AUTOSAR XML (schema 00046)
package /MICROSAR/BswM_swc
  4 x mode declaration group:
    ESH_Mode: initial-mode=STARTUP
      5 x mode:
        STARTUP
        RUN
        POSTRUN
        WAKEUP
        SHUTDOWN
    ESH_RunRequest: initial-mode=RELEASED
      mode RELEASED
      mode REQUESTED
    ModeDecl_ComFault_State: initial-mode=ComFaultPreCond_FAIL
      mode ComFaultPreCond_PASS
      mode ComFaultPreCond_FAIL
    ModeDecl_ComFault_State_WithKL15: initial-mode=ComFaultPreCondWithKL15_FAIL
      mode ComFaultPreCondWithKL15_FAIL
      mode ComFaultPreCondWithKL15_PASS
  data type mapping set BswMMappingSet  # Contains Mapping for ModeDeclarations Groups which are provided by BswM.
    mode-request-type-maps:
      implementation-data-type=BswM_ModeDecl_ComFault_State, mode-group=ModeDecl_ComFault_State
      implementation-data-type=BswM_ModeDecl_ComFault_State_WithKL15, mode-group=ModeDecl_ComFault_State_WithKL15
      implementation-data-type=BswM_ESH_Mode, mode-group=ESH_Mode
      implementation-data-type=BswM_ESH_RunRequest, mode-group=ESH_RunRequest
package /MICROSAR/BswM_swc/ComponentTypes
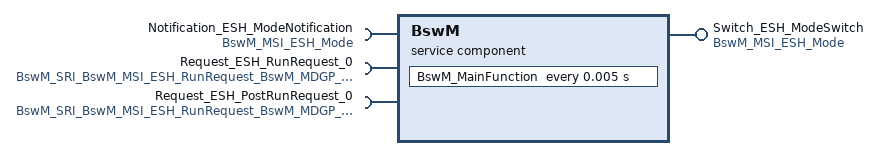
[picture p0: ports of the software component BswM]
  service sw component type BswM: category=SERVICE_COMPONENT
    provide port Switch_ESH_ModeSwitch: provided-interface=BswM_MSI_ESH_Mode
    require port Notification_ESH_ModeNotification: required-interface=BswM_MSI_ESH_Mode
    require port Request_ESH_RunRequest_0: nonqueued-receiver-com-spec{data-element=BswM_SRI_BswM_MSI_ESH_RunRequest_BswM_MDGP_ESH_RunRequest/requestedMode, handle-out-of-range-status=SILENT, init-value=RELEASED}, required-interface=BswM_SRI_BswM_MSI_ESH_RunRequest_BswM_MDGP_ESH_RunRequest
    require port Request_ESH_PostRunRequest_0: nonqueued-receiver-com-spec{data-element=BswM_SRI_BswM_MSI_ESH_RunRequest_BswM_MDGP_ESH_RunRequest/requestedMode, handle-out-of-range-status=SILENT, init-value=RELEASED}, required-interface=BswM_SRI_BswM_MSI_ESH_RunRequest_BswM_MDGP_ESH_RunRequest
    behavior BswMInternalBehavior: data-type-mapping=BswMMappingSet, handle-termination-and-restart=NO-SUPPORT, included-data-type-set=data-type=[BswM_ModeDecl_ComFault_State, BswM_ModeDecl_ComFault_State_WithKL15, BswM_ESH_Mode, BswM_ESH_RunRequest]
      timing event Timer_BswM_MainFunction: start-on-event=BswM_MainFunction, period=0.005
      port-api-options:
        enable-take-address=true, indirect-api=false, port=Switch_ESH_ModeSwitch
        enable-take-address=true, indirect-api=false, port=Notification_ESH_ModeNotification
        enable-take-address=true, indirect-api=false, port=Request_ESH_RunRequest_0
        enable-take-address=true, indirect-api=false, port=Request_ESH_PostRunRequest_0
      runnable BswM_MainFunction: mode-access-point=Notification_ESH_ModeNotification.BswM_MDGP_ESH_Mode
        data-receive-point-by-arguments:
          access DataReceivePointBswM_MainFunction_Request_ESH_RunRequest_0_requestedMode: accessed-variable=Request_ESH_RunRequest_0.requestedMode
          access DataReceivePointBswM_MainFunction_Request_ESH_PostRunRequest_0_requestedMode: accessed-variable=Request_ESH_PostRunRequest_0.requestedMode
        mode switch point ModeSwitchPointBswM_MainFunction_Switch_ESH_ModeSwitch_BswM_MDGP_ESH_Mode: mode-group=Switch_ESH_ModeSwitch.BswM_MDGP_ESH_Mode
  swc implementation BswMImplementation: programming-language=C, behavior=BswMInternalBehavior
package /MICROSAR/BswM_swc/DataTypes
  4 x impl type, all with category=TYPE_REFERENCE, range raw 0..255, implementation-data-type=uint8:
    BswM_ESH_Mode: compu {0=STARTUP, 1=RUN, 2=POSTRUN, 3=WAKEUP, 4=SHUTDOWN}  # Unique value for each user
    BswM_ESH_RunRequest: compu {0=RELEASED, 1=REQUESTED}  # Unique value for each user
    BswM_ModeDecl_ComFault_State: compu {1=ComFaultPreCond_PASS, 0=ComFaultPreCond_FAIL}  # Unique value for each user
    BswM_ModeDecl_ComFault_State_WithKL15: compu {0=ComFaultPreCondWithKL15_FAIL, 1=ComFaultPreCondWithKL15_PASS}  # Unique value for each user
package /MICROSAR/BswM_swc/Interfaces
  mode switch interface BswM_MSI_ESH_Mode: is-service=true, service-kind=BASIC-SOFTWARE-MODE-MANAGER
    mode group BswM_MDGP_ESH_Mode: type=ESH_Mode
  sender receiver interface BswM_SRI_BswM_MSI_ESH_Mode_BswM_MDGP_ESH_Mode: is-service=true, service-kind=BASIC-SOFTWARE-MODE-MANAGER
    data requestedMode: type=BswM_ESH_Mode
  mode switch interface BswM_MSI_ESH_RunRequest: is-service=true, service-kind=BASIC-SOFTWARE-MODE-MANAGER
    mode group BswM_MDGP_ESH_RunRequest: type=ESH_RunRequest
  sender receiver interface BswM_SRI_BswM_MSI_ESH_RunRequest_BswM_MDGP_ESH_RunRequest: is-service=true, service-kind=BASIC-SOFTWARE-MODE-MANAGER
    data requestedMode: type=BswM_ESH_RunRequest
  mode switch interface BswM_MSI_ModeDecl_ComFault_State: is-service=true, service-kind=BASIC-SOFTWARE-MODE-MANAGER
    mode group BswM_MDGP_ModeDecl_ComFault_State: type=ModeDecl_ComFault_State
  sender receiver interface BswM_SRI_BswM_MSI_ModeDecl_ComFault_State_BswM_MDGP_ModeDecl_ComFault_State: is-service=true, service-kind=BASIC-SOFTWARE-MODE-MANAGER
    data requestedMode: type=BswM_ModeDecl_ComFault_State
  mode switch interface BswM_MSI_ModeDecl_ComFault_State_WithKL15: is-service=true, service-kind=BASIC-SOFTWARE-MODE-MANAGER
    mode group BswM_MDGP_ModeDecl_ComFault_State_WithKL15: type=ModeDecl_ComFault_State_WithKL15
  sender receiver interface BswM_SRI_BswM_MSI_ModeDecl_ComFault_State_WithKL15_BswM_MDGP_ModeDecl_ComFault_State_WithKL15: is-service=true, service-kind=BASIC-SOFTWARE-MODE-MANAGER
    data requestedMode: type=BswM_ModeDecl_ComFault_State_WithKL15
